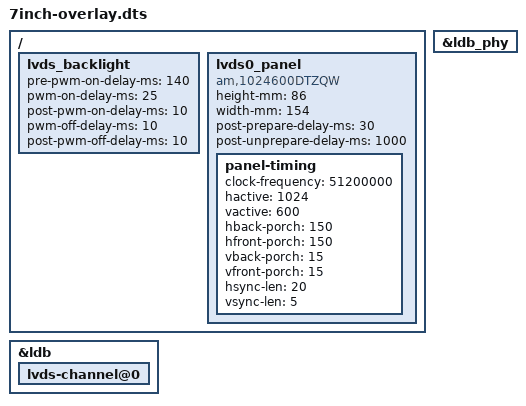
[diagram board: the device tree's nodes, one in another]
// SPDX-License-Identifier: (GPL-2.0+ OR MIT)
/*
 * Copyright 2023 ADLINK Technology Corp.
 *
 * Author: Po Cheng <po.cheng@adlinktech.com>
 */

/dts-v1/;
/plugin/;

/ {
	fragment@0 {
		target-path = "/";
		__overlay__ {
			lvds_backlight {
				pre-pwm-on-delay-ms = <140>;
				pwm-on-delay-ms = <25>;
				post-pwm-on-delay-ms = <10>;
				pwm-off-delay-ms = <10>;
				post-pwm-off-delay-ms = <10>;
				status = "okay";
			};
		};
	};

	fragment@1 {
		target-path = "/";
		__overlay__ {
			lvds0_panel {
				compatible = "am,1024600DTZQW", "panel-lvds";

				height-mm = <86>;
				width-mm = <154>;

				post-prepare-delay-ms = <30>;
				post-unprepare-delay-ms = <1000>;

				status = "okay";

				panel-timing {
					clock-frequency = <51200000>;
					hactive = <1024>;
					vactive = <600>;
					hback-porch = <150>;
					hfront-porch = <150>;
					vback-porch = <15>;
					vfront-porch = <15>;
					hsync-len = <20>;
					vsync-len = <5>;
				};
			};
		};
	};

	fragment@2 {
		target = <&ldb>;
		__overlay__ {
			status = "okay";
			lvds-channel@0 {
				status = "okay";
			};
		};
	};

	fragment@3 {
		target = <&ldb_phy>;
		__overlay__ {
			status = "okay";
		};
	};
};

